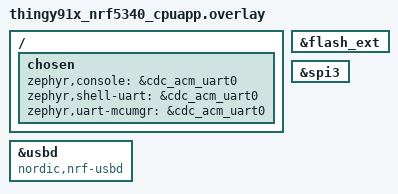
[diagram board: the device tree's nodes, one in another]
#include <thingy91x_nrf53_wifi.dtsi>

&usbd {
	compatible = "nordic,nrf-usbd";
	status = "okay";
};

/ {
	chosen {
		zephyr,console = &cdc_acm_uart0;
		zephyr,shell-uart = &cdc_acm_uart0;
		zephyr,uart-mcumgr = &cdc_acm_uart0;
	};
};

/* Enable external flash */
&flash_ext{
    status = "okay";
};

&spi3{
    status = "okay";
};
